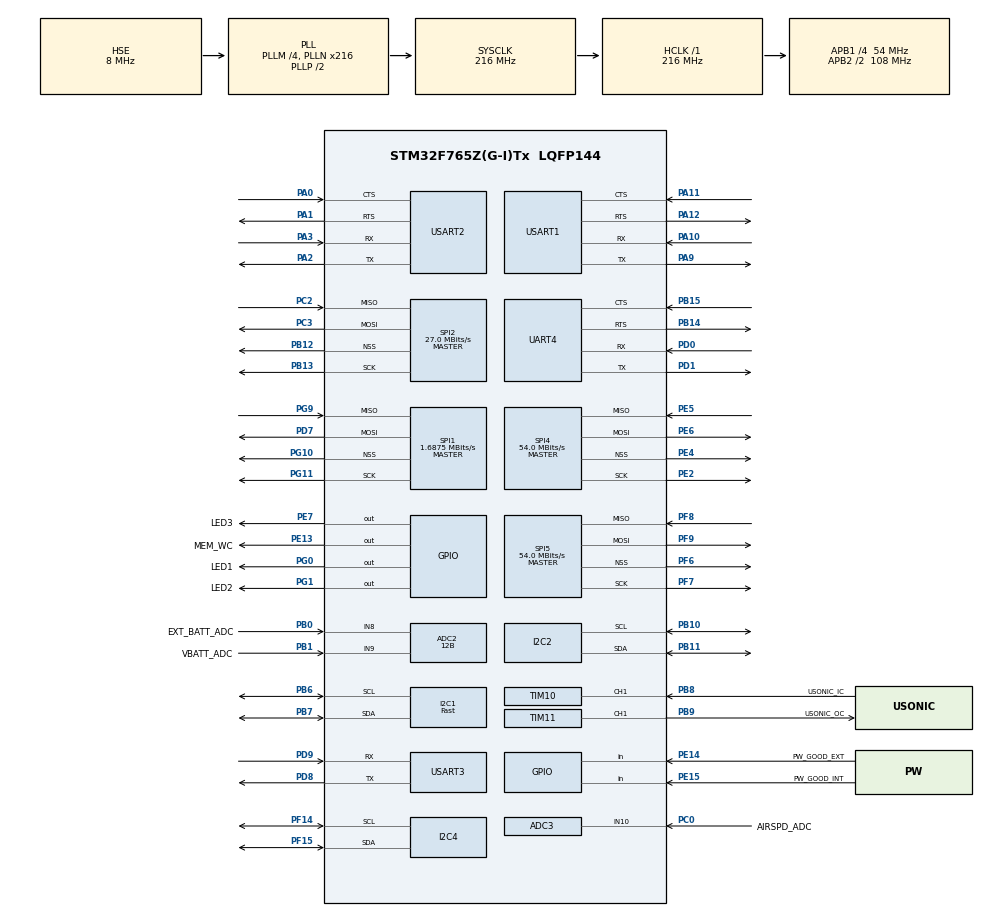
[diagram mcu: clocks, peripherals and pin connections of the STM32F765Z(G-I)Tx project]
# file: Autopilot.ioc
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ADC2.Channel-5\#ChannelRegularConversion=ADC_CHANNEL_8
ADC2.ClockPrescaler=ADC_CLOCK_SYNC_PCLK_DIV4
ADC2.ContinuousConvMode=DISABLE
ADC2.DMAContinuousRequests=DISABLE
ADC2.DataAlign=ADC_DATAALIGN_RIGHT
ADC2.DiscontinuousConvMode=DISABLE
ADC2.EOCSelection=ADC_EOC_SINGLE_CONV
ADC2.EnableAnalogWatchDog=false
ADC2.ExternalTrigConv=ADC_SOFTWARE_START
ADC2.ExternalTrigConvEdge=ADC_EXTERNALTRIGCONVEDGE_NONE
ADC2.InjNumberOfConversion=0
ADC2.NbrOfConversion=1
ADC2.NbrOfConversionFlag=1
ADC2.Rank-5\#ChannelRegularConversion=1
ADC2.Resolution=ADC_RESOLUTION_12B
ADC2.SamplingTime-5\#ChannelRegularConversion=ADC_SAMPLETIME_3CYCLES
ADC2.ScanConvMode=DISABLE
ADC3.Channel-0\#ChannelRegularConversion=ADC_CHANNEL_10
ADC3.ClockPrescaler=ADC_CLOCK_SYNC_PCLK_DIV4
ADC3.NbrOfConversionFlag=1
ADC3.Rank-0\#ChannelRegularConversion=1
ADC3.SamplingTime-0\#ChannelRegularConversion=ADC_SAMPLETIME_3CYCLES
FREERTOS.Tasks01=defaultTask,0,128,StartDefaultTask,Default,NULL,Dynamic,NULL,NULL;Interchip,0,128,Interchip_Run,As external,NULL,Dynamic,NULL,NULL
I2C1.I2C_Speed_Mode=I2C_Fast
I2C1.Timing=0x6000030D
I2C2.Timing=0x20404768
I2C4.Timing=0x20404768
Mcu.Family=STM32F7
Mcu.Name=STM32F765Z(G-I)Tx
Mcu.Package=LQFP144
NVIC.I2C1_EV_IRQn=true\:5\:0\:false\:false\:true\:true\:true
NVIC.I2C2_EV_IRQn=true\:5\:0\:false\:false\:true\:true\:true
NVIC.I2C4_EV_IRQn=true\:5\:0\:false\:false\:true\:true\:true
NVIC.PriorityGroup=NVIC_PRIORITYGROUP_4
NVIC.SPI1_IRQn=true\:1\:0\:true\:false\:true\:false\:true
NVIC.TIM1_UP_TIM10_IRQn=true\:5\:0\:true\:false\:true\:true\:true
NVIC.TIM4_IRQn=true\:0\:0\:false\:false\:true\:false\:false
NVIC.TIM6_DAC_IRQn=true\:5\:0\:false\:false\:true\:true\:true
NVIC.TimeBase=TIM4_IRQn
NVIC.TimeBaseIP=TIM4
NVIC.UART4_IRQn=true\:5\:0\:false\:false\:true\:true\:true
NVIC.USART1_IRQn=true\:5\:0\:false\:false\:true\:true\:true
NVIC.USART2_IRQn=true\:5\:0\:false\:false\:true\:true\:true
NVIC.USART3_IRQn=true\:5\:0\:false\:false\:true\:true\:true
PA0/WKUP.Mode=CTS_RTS
PA0/WKUP.Signal=USART2_CTS
PA1.Mode=CTS_RTS
PA1.Signal=USART2_RTS
PA10.Mode=Asynchronous
PA10.Signal=USART1_RX
PA11.Mode=CTS_RTS
PA11.Signal=USART1_CTS
PA12.Mode=CTS_RTS
PA12.Signal=USART1_RTS
PA13.Mode=Trace_Asynchronous_SW
PA13.Signal=SYS_JTMS-SWDIO
PA14.Mode=Trace_Asynchronous_SW
PA14.Signal=SYS_JTCK-SWCLK
PA2.Mode=Asynchronous
PA2.Signal=USART2_TX
PA3.Mode=Asynchronous
PA3.Signal=USART2_RX
PA9.Mode=Asynchronous
PA9.Signal=USART1_TX
PB0.GPIO_Label=EXT_BATT_ADC
PB0.Signal=ADCx_IN8
PB1.GPIO_Label=VBATT_ADC
PB1.Signal=ADCx_IN9
PB10.Mode=I2C
PB10.Signal=I2C2_SCL
PB11.Mode=I2C
PB11.Signal=I2C2_SDA
PB12.Mode=NSS_Signal_Hard_Output
PB12.Signal=SPI2_NSS
PB13.Mode=Full_Duplex_Master
PB13.Signal=SPI2_SCK
PB14.Mode=CTS_RTS
PB14.Signal=UART4_RTS
PB15.Mode=CTS_RTS
PB15.Signal=UART4_CTS
PB3.Mode=Trace_Asynchronous_SW
PB3.Signal=SYS_JTDO-SWO
PB6.Mode=I2C
PB6.Signal=I2C1_SCL
PB7.Mode=I2C
PB7.Signal=I2C1_SDA
PB8.GPIO_Label=USONIC_IC
PB8.Signal=S_TIM10_CH1
PB9.GPIO_Label=USONIC_OC
PB9.Signal=S_TIM11_CH1
PC0.GPIO_Label=AIRSPD_ADC
PC0.Signal=ADCx_IN10
PC14/OSC32_IN.Mode=LSE-External-Oscillator
PC14/OSC32_IN.Signal=RCC_OSC32_IN
PC15/OSC32_OUT.Mode=LSE-External-Oscillator
PC15/OSC32_OUT.Signal=RCC_OSC32_OUT
PC2.Mode=Full_Duplex_Master
PC2.Signal=SPI2_MISO
PC3.Mode=Full_Duplex_Master
PC3.Signal=SPI2_MOSI
PD0.Mode=Asynchronous
PD0.Signal=UART4_RX
PD1.Mode=Asynchronous
PD1.Signal=UART4_TX
PD7.Mode=Full_Duplex_Master
PD7.Signal=SPI1_MOSI
PD8.Mode=Asynchronous
PD8.Signal=USART3_TX
PD9.Mode=Asynchronous
PD9.Signal=USART3_RX
PE13.GPIO_Label=MEM_WC
PE13.PinState=GPIO_PIN_RESET
PE13.Signal=GPIO_Output
PE14.GPIO_Label=PW_GOOD_EXT
PE14.GPIO_PuPd=GPIO_PULLDOWN
PE14.Signal=GPIO_Input
PE15.GPIO_Label=PW_GOOD_INT
PE15.GPIO_PuPd=GPIO_PULLDOWN
PE15.Signal=GPIO_Input
PE2.Mode=Full_Duplex_Master
PE2.Signal=SPI4_SCK
PE4.Mode=NSS_Signal_Hard_Output
PE4.Signal=SPI4_NSS
PE5.Mode=Full_Duplex_Master
PE5.Signal=SPI4_MISO
PE6.Mode=Full_Duplex_Master
PE6.Signal=SPI4_MOSI
PE7.GPIO_Label=LED3
PE7.PinState=GPIO_PIN_RESET
PE7.Signal=GPIO_Output
PF14.Mode=I2C
PF14.Signal=I2C4_SCL
PF15.Mode=I2C
PF15.Signal=I2C4_SDA
PF6.Mode=NSS_Signal_Hard_Output
PF6.Signal=SPI5_NSS
PF7.Mode=Full_Duplex_Master
PF7.Signal=SPI5_SCK
PF8.Mode=Full_Duplex_Master
PF8.Signal=SPI5_MISO
PF9.Mode=Full_Duplex_Master
PF9.Signal=SPI5_MOSI
PG0.GPIO_Label=LED1
PG0.Signal=GPIO_Output
PG1.GPIO_Label=LED2
PG1.Signal=GPIO_Output
PG10.Mode=NSS_Signal_Hard_Output
PG10.Signal=SPI1_NSS
PG11.Mode=Full_Duplex_Master
PG11.Signal=SPI1_SCK
PG9.Mode=Full_Duplex_Master
PG9.Signal=SPI1_MISO
PH0/OSC_IN.Mode=HSE-External-Oscillator
PH0/OSC_IN.Signal=RCC_OSC_IN
PH1/OSC_OUT.Mode=HSE-External-Oscillator
PH1/OSC_OUT.Signal=RCC_OSC_OUT
ProjectManager.HeapSize=0x200
ProjectManager.StackSize=0x400
ProjectManager.TargetToolchain=Makefile
RCC.AHBFreq_Value=216000000
RCC.APB1CLKDivider=RCC_HCLK_DIV4
RCC.APB1Freq_Value=54000000
RCC.APB1TimFreq_Value=108000000
RCC.APB2CLKDivider=RCC_HCLK_DIV2
RCC.APB2Freq_Value=108000000
RCC.APB2TimFreq_Value=216000000
RCC.CortexFreq_Value=216000000
RCC.HCLKFreq_Value=216000000
RCC.HSE_VALUE=8000000
RCC.HSI_VALUE=16000000
RCC.PLLM=4
RCC.PLLN=216
RCC.PLLSourceVirtual=RCC_PLLSOURCE_HSE
RCC.RCC_TIM_PRescaler_Selection=RCC_TIMPRES_DESACTIVATED
RCC.SYSCLKFreq_VALUE=216000000
RCC.SYSCLKSource=RCC_SYSCLKSOURCE_PLLCLK
RCC.USBFreq_Value=216000000
RCC.VCOOutputFreq_Value=432000000
SH.ADCx_IN10.0=ADC3_IN10,IN10
SH.ADCx_IN8.0=ADC2_IN8,IN8
SH.ADCx_IN9.0=ADC2_IN9,IN9
SH.S_TIM10_CH1.0=TIM10_CH1,Input_Capture1_from_TI1
SH.S_TIM11_CH1.0=TIM11_CH1,Output Compare1 CH1
SPI1.BaudRatePrescaler=SPI_BAUDRATEPRESCALER_64
SPI1.CRCCalculation=SPI_CRCCALCULATION_DISABLE
SPI1.CalculateBaudRate=1.6875 MBits/s
SPI1.DataSize=SPI_DATASIZE_16BIT
SPI1.Direction=SPI_DIRECTION_2LINES
SPI1.Mode=SPI_MODE_MASTER
SPI1.NSSPMode=SPI_NSS_PULSE_ENABLE
SPI1.VirtualNSS=VM_NSSHARD
SPI1.VirtualType=VM_MASTER
SPI2.BaudRatePrescaler=SPI_BAUDRATEPRESCALER_2
SPI2.CalculateBaudRate=27.0 MBits/s
SPI2.Direction=SPI_DIRECTION_2LINES
SPI2.Mode=SPI_MODE_MASTER
SPI2.VirtualNSS=VM_NSSHARD
SPI2.VirtualType=VM_MASTER
SPI4.BaudRatePrescaler=SPI_BAUDRATEPRESCALER_2
SPI4.CalculateBaudRate=54.0 MBits/s
SPI4.DataSize=SPI_DATASIZE_4BIT
SPI4.Direction=SPI_DIRECTION_2LINES
SPI4.Mode=SPI_MODE_MASTER
SPI4.VirtualNSS=VM_NSSHARD
SPI4.VirtualType=VM_MASTER
SPI5.BaudRatePrescaler=SPI_BAUDRATEPRESCALER_2
SPI5.CalculateBaudRate=54.0 MBits/s
SPI5.Direction=SPI_DIRECTION_2LINES
SPI5.Mode=SPI_MODE_MASTER
SPI5.VirtualNSS=VM_NSSHARD
SPI5.VirtualType=VM_MASTER
TIM10.Channel=TIM_CHANNEL_1
TIM10.ICPolarity_CH1=TIM_INPUTCHANNELPOLARITY_BOTHEDGE
TIM11.Channel=TIM_CHANNEL_1
TIM6.AutoReloadPreload=TIM_AUTORELOAD_PRELOAD_ENABLE
TIM6.Period=65000
TIM6.Prescaler=216
UART4.WordLength=WORDLENGTH_8B
USART1.VirtualMode-Asynchronous=VM_ASYNC
USART1.WordLength=WORDLENGTH_8B
USART2.VirtualMode-Asynchronous=VM_ASYNC
USART2.WordLength=WORDLENGTH_8B
USART3.VirtualMode-Asynchronous=VM_ASYNC
USART3.WordLength=WORDLENGTH_8B
VP_CRC_VS_CRC.Mode=CRC_Activate
VP_FREERTOS_VS_ENABLE.Mode=Enabled
VP_SYS_VS_tim4.Mode=TIM4
VP_TIM10_VS_ClockSourceINT.Mode=Enable_Timer
VP_TIM10_VS_OPM.Mode=OPM_bit
VP_TIM11_VS_ClockSourceINT.Mode=Enable_Timer
VP_TIM11_VS_OPM.Mode=OPM_bit
VP_TIM6_VS_ClockSourceINT.Mode=Enable_Timer
board=Autopilot

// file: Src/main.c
/**
  ******************************************************************************
  * File Name          : main.c
  * Description        : Main program body
  ******************************************************************************
  * This notice applies to any and all portions of this file
  * that are not between comment pairs USER CODE BEGIN and
  * USER CODE END. Other portions of this file, whether
  * inserted by the user or by software development tools
  * are owned by their respective copyright owners.
  *
  * Copyright (c) 2018 STMicroelectronics International N.V.
  * All rights reserved.
  *
  * Redistribution and use in source and binary forms, with or without
  * modification, are permitted, provided that the following conditions are met:
  *
  * 1. Redistribution of source code must retain the above copyright notice,
  *    this list of conditions and the following disclaimer.
  * 2. Redistributions in binary form must reproduce the above copyright notice,
  *    this list of conditions and the following disclaimer in the documentation
  *    and/or other materials provided with the distribution.
  * 3. Neither the name of STMicroelectronics nor the names of other
  *    contributors to this software may be used to endorse or promote products
  *    derived from this software without specific written permission.
  * 4. This software, including modifications and/or derivative works of this
  *    software, must execute solely and exclusively on microcontroller or
  *    microprocessor devices manufactured by or for STMicroelectronics.
  * 5. Redistribution and use of this software other than as permitted under
  *    this license is void and will automatically terminate your rights under
  *    this license.
  *
  * THIS SOFTWARE IS PROVIDED BY STMICROELECTRONICS AND CONTRIBUTORS "AS IS"
  * AND ANY EXPRESS, IMPLIED OR STATUTORY WARRANTIES, INCLUDING, BUT NOT
  * LIMITED TO, THE IMPLIED WARRANTIES OF MERCHANTABILITY, FITNESS FOR A
  * PARTICULAR PURPOSE AND NON-INFRINGEMENT OF THIRD PARTY INTELLECTUAL PROPERTY
  * RIGHTS ARE DISCLAIMED TO THE FULLEST EXTENT PERMITTED BY LAW. IN NO EVENT
  * SHALL STMICROELECTRONICS OR CONTRIBUTORS BE LIABLE FOR ANY DIRECT, INDIRECT,
  * INCIDENTAL, SPECIAL, EXEMPLARY, OR CONSEQUENTIAL DAMAGES (INCLUDING, BUT NOT
  * LIMITED TO, PROCUREMENT OF SUBSTITUTE GOODS OR SERVICES; LOSS OF USE, DATA,
  * OR PROFITS; OR BUSINESS INTERRUPTION) HOWEVER CAUSED AND ON ANY THEORY OF
  * LIABILITY, WHETHER IN CONTRACT, STRICT LIABILITY, OR TORT (INCLUDING
  * NEGLIGENCE OR OTHERWISE) ARISING IN ANY WAY OUT OF THE USE OF THIS SOFTWARE,
  * EVEN IF ADVISED OF THE POSSIBILITY OF SUCH DAMAGE.
  *
  ******************************************************************************
  */

#include "main.h"
#include "stm32f7xx_hal.h"
#include "cmsis_os.h"
#include "adc.h"
#include "crc.h"
#include "i2c.h"
#include "spi.h"
#include "tim.h"
#include "usart.h"
#include "gpio.h"

/* USER CODE BEGIN Includes */
#include "debug.h"
#include "eeprom.h"
/* USER CODE END Includes */

/* USER CODE BEGIN PV */
/* Private variables ---------------------------------------------------------*/

/* USER CODE END PV */

void SystemClock_Config(void);
void MX_FREERTOS_Init(void);

/* USER CODE BEGIN PFP */
/* Private function prototypes -----------------------------------------------*/

/* USER CODE END PFP */

int main(void)
{

  /* MCU Configuration----------------------------------------------------------*/

  /* Reset of all peripherals, Initializes the Flash interface and the Systick. */
  HAL_Init();

  /* Configure the system clock */
  SystemClock_Config();

  /* Initialize all configured peripherals */
  MX_GPIO_Init();
  MX_SPI5_Init();
  MX_SPI4_Init();
  MX_I2C1_Init();
  MX_I2C2_Init();
  MX_I2C4_Init();
  MX_USART2_UART_Init();
  MX_SPI1_Init();
  MX_ADC3_Init();
  MX_ADC2_Init();
  MX_UART4_Init();
  MX_USART3_UART_Init();
  MX_USART1_UART_Init();
  MX_SPI2_Init();
  MX_TIM10_Init();
  MX_TIM11_Init();
  MX_CRC_Init();
  MX_TIM6_Init();

  /* USER CODE BEGIN 2 */
  debug("\n\nStarting up...");
  debug("Compiled on %s at %s", __DATE__, __TIME__);

  HAL_GPIO_WritePin(LED1_GPIO_Port, LED1_Pin, GPIO_PIN_SET);

  EEPROM_Init();
  /* USER CODE END 2 */

  /* Call init function for freertos objects (in freertos.c) */
  MX_FREERTOS_Init();

  /* Start scheduler */
  osKernelStart();

  /* We should never get here as control is now taken by the scheduler */

  /* Infinite loop */
  while (1)
  {

  }

}

/** System Clock Configuration
*/
void SystemClock_Config(void)
{

  RCC_OscInitTypeDef RCC_OscInitStruct;
  RCC_ClkInitTypeDef RCC_ClkInitStruct;
  RCC_PeriphCLKInitTypeDef PeriphClkInitStruct;

    /**Configure the main internal regulator output voltage
    */
  __HAL_RCC_PWR_CLK_ENABLE();

  __HAL_PWR_VOLTAGESCALING_CONFIG(PWR_REGULATOR_VOLTAGE_SCALE1);

    /**Initializes the CPU, AHB and APB busses clocks
    */
  RCC_OscInitStruct.OscillatorType = RCC_OSCILLATORTYPE_HSE;
  RCC_OscInitStruct.HSEState = RCC_HSE_ON;
  RCC_OscInitStruct.PLL.PLLState = RCC_PLL_ON;
  RCC_OscInitStruct.PLL.PLLSource = RCC_PLLSOURCE_HSE;
  RCC_OscInitStruct.PLL.PLLM = 4;
  RCC_OscInitStruct.PLL.PLLN = 216;
  RCC_OscInitStruct.PLL.PLLP = RCC_PLLP_DIV2;
  RCC_OscInitStruct.PLL.PLLQ = 2;
  if (HAL_RCC_OscConfig(&RCC_OscInitStruct) != HAL_OK)
  {
    _Error_Handler(__FILE__, __LINE__);
  }

    /**Activate the Over-Drive mode
    */
  if (HAL_PWREx_EnableOverDrive() != HAL_OK)
  {
    _Error_Handler(__FILE__, __LINE__);
  }

    /**Initializes the CPU, AHB and APB busses clocks
    */
  RCC_ClkInitStruct.ClockType = RCC_CLOCKTYPE_HCLK|RCC_CLOCKTYPE_SYSCLK
                              |RCC_CLOCKTYPE_PCLK1|RCC_CLOCKTYPE_PCLK2;
  RCC_ClkInitStruct.SYSCLKSource = RCC_SYSCLKSOURCE_PLLCLK;
  RCC_ClkInitStruct.AHBCLKDivider = RCC_SYSCLK_DIV1;
  RCC_ClkInitStruct.APB1CLKDivider = RCC_HCLK_DIV4;
  RCC_ClkInitStruct.APB2CLKDivider = RCC_HCLK_DIV2;

  if (HAL_RCC_ClockConfig(&RCC_ClkInitStruct, FLASH_LATENCY_7) != HAL_OK)
  {
    _Error_Handler(__FILE__, __LINE__);
  }

  PeriphClkInitStruct.PeriphClockSelection = RCC_PERIPHCLK_USART1|RCC_PERIPHCLK_USART2
                              |RCC_PERIPHCLK_USART3|RCC_PERIPHCLK_UART4
                              |RCC_PERIPHCLK_I2C1|RCC_PERIPHCLK_I2C2
                              |RCC_PERIPHCLK_I2C4;
  PeriphClkInitStruct.Usart1ClockSelection = RCC_USART1CLKSOURCE_PCLK2;
  PeriphClkInitStruct.Usart2ClockSelection = RCC_USART2CLKSOURCE_PCLK1;
  PeriphClkInitStruct.Usart3ClockSelection = RCC_USART3CLKSOURCE_PCLK1;
  PeriphClkInitStruct.Uart4ClockSelection = RCC_UART4CLKSOURCE_PCLK1;
  PeriphClkInitStruct.I2c1ClockSelection = RCC_I2C1CLKSOURCE_PCLK1;
  PeriphClkInitStruct.I2c2ClockSelection = RCC_I2C2CLKSOURCE_PCLK1;
  PeriphClkInitStruct.I2c4ClockSelection = RCC_I2C4CLKSOURCE_PCLK1;
  if (HAL_RCCEx_PeriphCLKConfig(&PeriphClkInitStruct) != HAL_OK)
  {
    _Error_Handler(__FILE__, __LINE__);
  }

    /**Configure the Systick interrupt time
    */
  HAL_SYSTICK_Config(HAL_RCC_GetHCLKFreq()/1000);

    /**Configure the Systick
    */
  HAL_SYSTICK_CLKSourceConfig(SYSTICK_CLKSOURCE_HCLK);

  /* SysTick_IRQn interrupt configuration */
  HAL_NVIC_SetPriority(SysTick_IRQn, 15, 0);
}

void HAL_TIM_PeriodElapsedCallback(TIM_HandleTypeDef *htim)
{
  if (htim->Instance == TIM4) {
    HAL_IncTick();
  }
}

void _Error_Handler(char * file, int line)
{
  /* USER CODE BEGIN Error_Handler_Debug */
  /* User can add his own implementation to report the HAL error return state */
  debug("ERROR: [%s] : %d", file, line);
  while(1)
  {
  }
  /* USER CODE END Error_Handler_Debug */
}

/************************ (C) COPYRIGHT STMicroelectronics *****END OF FILE****/

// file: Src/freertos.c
/* USER CODE BEGIN Header */
/**
  ******************************************************************************
  * File Name          : freertos.c
  * Description        : Code for freertos applications
  ******************************************************************************
  * This notice applies to any and all portions of this file
  * that are not between comment pairs USER CODE BEGIN and
  * USER CODE END. Other portions of this file, whether
  * inserted by the user or by software development tools
  * are owned by their respective copyright owners.
  *
  * Copyright (c) 2019 STMicroelectronics International N.V.
  * All rights reserved.
  *
  * Redistribution and use in source and binary forms, with or without
  * modification, are permitted, provided that the following conditions are met:
  *
  * 1. Redistribution of source code must retain the above copyright notice,
  *    this list of conditions and the following disclaimer.
  * 2. Redistributions in binary form must reproduce the above copyright notice,
  *    this list of conditions and the following disclaimer in the documentation
  *    and/or other materials provided with the distribution.
  * 3. Neither the name of STMicroelectronics nor the names of other
  *    contributors to this software may be used to endorse or promote products
  *    derived from this software without specific written permission.
  * 4. This software, including modifications and/or derivative works of this
  *    software, must execute solely and exclusively on microcontroller or
  *    microprocessor devices manufactured by or for STMicroelectronics.
  * 5. Redistribution and use of this software other than as permitted under
  *    this license is void and will automatically terminate your rights under
  *    this license.
  *
  * THIS SOFTWARE IS PROVIDED BY STMICROELECTRONICS AND CONTRIBUTORS "AS IS"
  * AND ANY EXPRESS, IMPLIED OR STATUTORY WARRANTIES, INCLUDING, BUT NOT
  * LIMITED TO, THE IMPLIED WARRANTIES OF MERCHANTABILITY, FITNESS FOR A
  * PARTICULAR PURPOSE AND NON-INFRINGEMENT OF THIRD PARTY INTELLECTUAL PROPERTY
  * RIGHTS ARE DISCLAIMED TO THE FULLEST EXTENT PERMITTED BY LAW. IN NO EVENT
  * SHALL STMICROELECTRONICS OR CONTRIBUTORS BE LIABLE FOR ANY DIRECT, INDIRECT,
  * INCIDENTAL, SPECIAL, EXEMPLARY, OR CONSEQUENTIAL DAMAGES (INCLUDING, BUT NOT
  * LIMITED TO, PROCUREMENT OF SUBSTITUTE GOODS OR SERVICES; LOSS OF USE, DATA,
  * OR PROFITS; OR BUSINESS INTERRUPTION) HOWEVER CAUSED AND ON ANY THEORY OF
  * LIABILITY, WHETHER IN CONTRACT, STRICT LIABILITY, OR TORT (INCLUDING
  * NEGLIGENCE OR OTHERWISE) ARISING IN ANY WAY OUT OF THE USE OF THIS SOFTWARE,
  * EVEN IF ADVISED OF THE POSSIBILITY OF SUCH DAMAGE.
  *
  ******************************************************************************
  */
/* USER CODE END Header */

#include "FreeRTOS.h"
#include "task.h"
#include "main.h"
#include "cmsis_os.h"

osThreadId defaultTaskHandle;
osThreadId InterchipHandle;
osThreadId AttitudeHandle;

void StartDefaultTask(void const * argument);
extern void Interchip_Run(void const * argument);

void MX_FREERTOS_Init(void); /* (MISRA C 2004 rule 8.1) */

void MX_FREERTOS_Init(void) {

  /* Create the thread(s) */
  /* definition and creation of defaultTask */
  osThreadDef(defaultTask, StartDefaultTask, osPriorityNormal, 0, 128);
  defaultTaskHandle = osThreadCreate(osThread(defaultTask), NULL);

  /* definition and creation of Interchip */
  osThreadDef(Interchip, Interchip_Run, osPriorityNormal, 0, 128);
  InterchipHandle = osThreadCreate(osThread(Interchip), NULL);

}

void StartDefaultTask(void const * argument)
{

  for(;;)
  {
    osDelay(1);
  }
}

/************************ (C) COPYRIGHT STMicroelectronics *****END OF FILE****/
